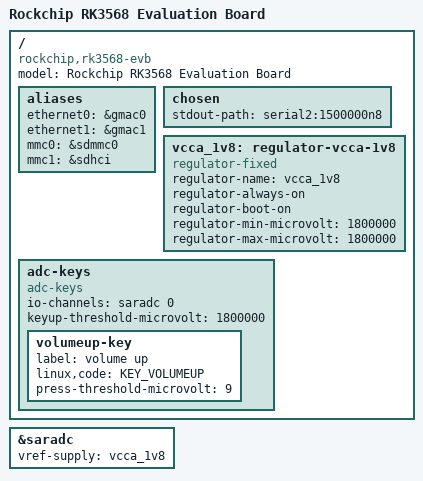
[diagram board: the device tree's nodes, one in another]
// SPDX-License-Identifier: (GPL-2.0+ OR MIT)
/*
 * LB2004 (Sunwintac SW-001 / ophub LB2004 / Skyworth LB2004-A4091) — U-Boot DT
 * 
 * Based on the rockchip,rk3568-evb DTB from the factory lb2004 firmware
 * (U-Boot DTB at 0x1da226 in the eMMC dump, model = "Rockchip RK3568 Evaluation
 * Board"). That DTB has only the nodes U-Boot needs plus an adc-keys node
 * for Recovery / volumeup. The kernel DTB (dts/upstream/rk3566-lb2004.dts)
 * is passed separately via fdtfile env var.
 *
 * ADC key ladder (SARADC ch0):
 *   volumeup-key, label "volume up", press-threshold-microvolt = <9>
 *   Measured on a working Debian LB2004 (2026-09-16): idle raw = 1023
 *   (1.8 V full scale), pressed raw = 19..23 (~0.035 V).
 *   rockchip_dnl_key_pressed() in board/rockchip/lb2004_rk3566/board.c
 *   uses raw < 100 as the press band (wide margins on both sides).
 *   => rockchip_dnl_mode_check() => BOOT_BROM_DOWNLOAD (maskrom/rockusb)
 */

#include <dt-bindings/input/input.h>
#include "rk3568.dtsi"

/ {
	model = "Rockchip RK3568 Evaluation Board";
	compatible = "rockchip,rk3568-evb", "rockchip,rk3568";

	aliases {
		ethernet0 = &gmac0;
		ethernet1 = &gmac1;
		mmc0 = &sdmmc0;
		mmc1 = &sdhci;
	};

	chosen {
		stdout-path = "serial2:1500000n8";
	};

	/* SARADC VREF — adc-keys ch0 needs 1.8V rail */
	vcca_1v8: regulator-vcca-1v8 {
		compatible = "regulator-fixed";
		regulator-name = "vcca_1v8";
		regulator-always-on;
		regulator-boot-on;
		regulator-min-microvolt = <1800000>;
		regulator-max-microvolt = <1800000>;
	};

	/* SARADC 1-key keypad (volume up = Recovery/download), matches factory */
	adc-keys {
		compatible = "adc-keys";
		io-channels = <&saradc 0>;
		io-channel-names = "buttons";
		keyup-threshold-microvolt = <1800000>;
		status = "okay";
		bootph-all;

		volumeup-key {
			label = "volume up";
			linux,code = <KEY_VOLUMEUP>;
			press-threshold-microvolt = <9>;
			bootph-all;
		};
	};
};

/* SARADC: vref from vcca_1v8, needed by adc-keys */
&saradc {
	vref-supply = <&vcca_1v8>;
	status = "okay";
};
